VERSION ""

NS_ :

BS_:

BU_: ESX_3CS ION_BMS SEG_BRM_Drive

BO_ 3221225472 VECTOR__INDEPENDENT_SIG_MSG: 0 Vector__XXX
 SG_ Edrv_iAct_LSB : 0|8@1+ (1,0) [0|255] "" Vector__XXX
 SG_ Edrv_iAct_MSB : 0|2@1+ (1,0) [0|3] "A" Vector__XXX
 SG_ Edrv_nAct_LSB : 0|4@1+ (1,0) [0|15] "" Vector__XXX
 SG_ Edrv_nAct_MSB : 0|1@1+ (1,0) [0|1] "rpm" Vector__XXX
 SG_ Edrv_nAct_SB : 0|8@1+ (1,0) [0|255] "" Vector__XXX
 SG_ Edrv_nrAlvCntrAct : 0|4@1+ (1,0) [0|15] "" Vector__XXX
 SG_ Edrv_nrChksAct : 0|8@1+ (1,0) [0|255] "" Vector__XXX
 SG_ Edrv_stOperModAct : 0|4@1+ (1,0) [0|15] "" Vector__XXX
 SG_ Edrv_stRunAct : 0|3@1+ (1,0) [0|7] "" Vector__XXX
 SG_ Edrv_tqAct_LSB : 0|7@1+ (1,0) [0|127] "" Vector__XXX
 SG_ Edrv_tqAct_MSB : 0|4@1+ (1,0) [0|15] "Nm" Vector__XXX
 SG_ Edrv_uAct_LSB : 0|6@1+ (1,0) [0|63] "" Vector__XXX
 SG_ Edrv_uAct_MSB : 0|4@1+ (1,0) [0|15] "V" Vector__XXX
 SG_ Edrv_nrAlvCntrDern : 0|4@1+ (1,0) [0|15] "" Vector__XXX
 SG_ Edrv_nrChksDern : 0|8@1+ (1,0) [0|255] "" Vector__XXX
 SG_ Edrv_ratTCritIvtr : 0|7@1+ (1,0) [0|127] "%" Vector__XXX
 SG_ Edrv_ratTCritMac_LSB : 0|6@1+ (1,0) [0|63] "%" Vector__XXX
 SG_ Edrv_ratTCritMac_MSB : 0|1@1+ (1,0) [0|1] "%" Vector__XXX
 SG_ Edrv_stActDern : 0|4@1+ (1,0) [0|15] "" Vector__XXX
 SG_ Edrv_stFltId_LSB : 0|7@1+ (1,0) [0|127] "" Vector__XXX
 SG_ Edrv_stFltId_MSB : 0|2@1+ (1,0) [0|3] "" Vector__XXX
 SG_ Edrv_tqMaxAvl_LSB : 0|4@1+ (1,0) [0|15] "" Vector__XXX
 SG_ Edrv_tqMaxAvl_MSB : 0|6@1+ (1,0) [0|63] "" Vector__XXX
 SG_ Edrv_tqMinAvl_LSB : 0|2@1+ (1,0) [0|3] "" Vector__XXX
 SG_ Edrv_tqMinAvl_MSB : 0|8@1+ (1,0) [0|255] "" Vector__XXX
 SG_ Eem_iMaxEdrv : 0|8@1+ (2,0) [0|510] "A" Vector__XXX
 SG_ Eem_iMinEdrv : 0|8@1+ (2,-510) [-510|0] "A" Vector__XXX
 SG_ Eem_nrAlvCntrLim : 0|4@1+ (1,0) [0|15] "" Vector__XXX
 SG_ Eem_nrChksLim : 0|8@1+ (1,0) [0|255] "" Vector__XXX
 SG_ Eem_rMvbEdrv : 0|8@1+ (0.005,0.005) [0.005|1.28] "Ohm" Vector__XXX
 SG_ Eem_uDesEdrv : 0|8@1+ (0.1,30) [30|55.5] "V" Vector__XXX
 SG_ Eem_uMaxEdrv : 0|8@1+ (0.2,10) [10|61] "V" Vector__XXX
 SG_ Eem_uMinEdrv : 0|8@1+ (0.2,10) [10|61] "V" Vector__XXX
 SG_ Byte2 : 0|8@1+ (1,0) [0|255] "" Vector__XXX
 SG_ Byte3 : 0|8@1+ (1,0) [0|255] "" Vector__XXX
 SG_ Byte4 : 0|8@1+ (1,0) [0|255] "" Vector__XXX
 SG_ Byte5 : 0|8@1+ (1,0) [0|255] "" Vector__XXX
 SG_ Byte6 : 0|8@1+ (1,0) [0|255] "" Vector__XXX
 SG_ Pt_nrAlvCntrDes : 0|4@1+ (1,0) [0|15] "" Vector__XXX
 SG_ Pt_nrChksDes : 0|8@1+ (1,0) [0|255] "" Vector__XXX
 SG_ Pt_stOperModDesEdrv : 0|4@1+ (1,0) [0|15] "" Vector__XXX
 SG_ Byte_4 : 0|8@1+ (1,0) [0|255] "" Vector__XXX
 SG_ Byte_5 : 0|8@1+ (1,0) [0|255] "" Vector__XXX
 SG_ Byte_6 : 0|8@1+ (1,0) [0|255] "" Vector__XXX
 SG_ Pt_dAirPresEdrv : 0|8@1+ (5,300) [300|1575] "hPa" Vector__XXX
 SG_ Pt_nrAlvCntrVeh1 : 0|4@1+ (1,0) [0|15] "" Vector__XXX
 SG_ Pt_nrChksVeh1 : 0|8@1+ (1,0) [0|255] "" Vector__XXX
 SG_ Pt_tAmbEdrv : 0|8@1+ (1,-40) [-40|215] "�C" Vector__XXX
 SG_ Byte_2 : 0|8@1+ (1,0) [0|255] "" Vector__XXX
 SG_ Byte_3 : 0|8@1+ (1,0) [0|255] "" Vector__XXX
 SG_ Byte_4 : 0|8@1+ (1,0) [0|255] "" Vector__XXX
 SG_ Byte_5 : 0|8@1+ (1,0) [0|255] "" Vector__XXX
 SG_ Pt_nrAlvCntrVeh2 : 0|4@1+ (1,0) [0|15] "" Vector__XXX
 SG_ Pt_nrChksVeh2 : 0|8@1+ (1,0) [0|255] "" Vector__XXX
 SG_ Data_1 : 0|8@1+ (1,0) [0|255] "" Vector__XXX
 SG_ Data_2 : 0|8@1+ (1,0) [0|255] "" Vector__XXX
 SG_ Data_3 : 0|8@1+ (1,0) [0|255] "" Vector__XXX
 SG_ Data_4 : 0|8@1+ (1,0) [0|255] "" Vector__XXX
 SG_ Data_5 : 0|8@1+ (1,0) [0|255] "" Vector__XXX
 SG_ Data_6 : 0|8@1+ (1,0) [0|255] "" Vector__XXX
 SG_ Data_7 : 0|8@1+ (1,0) [0|255] "" Vector__XXX
 SG_ Data_8 : 0|8@1+ (1,0) [0|255] "" Vector__XXX
 SG_ Battery_Voltage_LSB : 0|8@1+ (1,0) [0|255] "" Vector__XXX
 SG_ Battery_Voltage_MSB2 : 0|8@1+ (1,0) [0|255] "" Vector__XXX
 SG_ Battery_Voltage_MSB3 : 0|8@1+ (1,0) [0|255] "" Vector__XXX
 SG_ Battery_Voltage_MSB4 : 0|8@1+ (1,0) [0|255] "" Vector__XXX
 SG_ Max_Voltage_LSB : 0|8@1+ (1,0) [0|255] "" Vector__XXX
 SG_ Max_Voltage_MSB : 0|8@1+ (1,0) [0|255] "" Vector__XXX
 SG_ Min_Voltage_LSB : 0|8@1+ (1,0) [0|255] "" Vector__XXX
 SG_ Min_Voltage_MSB : 0|8@1+ (1,0) [0|255] "" Vector__XXX
 SG_ Battery_Current_LSB : 0|8@1+ (1,0) [0|255] "" Vector__XXX
 SG_ Battery_Current_MSB2 : 0|8@1+ (1,0) [0|255] "" Vector__XXX
 SG_ Battery_Current_MSB3 : 0|8@1+ (1,0) [0|255] "" Vector__XXX
 SG_ Battery_Current_MSB4 : 0|8@1+ (1,0) [0|255] "" Vector__XXX
 SG_ Temperature_Cell_Max_LSB : 0|8@1+ (1,0) [0|255] "" Vector__XXX
 SG_ Temperature_Cell_Max_MSB : 0|8@1+ (1,0) [0|255] "" Vector__XXX
 SG_ Temperature_Cell_Mean_LSB : 0|8@1+ (1,0) [0|255] "" Vector__XXX
 SG_ Temperature_Cell_Mean_MSB : 0|8@1+ (1,0) [0|255] "" Vector__XXX
 SG_ Temperature_Cell_Min_LSB : 0|8@1+ (1,0) [0|255] "" Vector__XXX
 SG_ Temperature_Cell_Min_MSB : 0|8@1+ (1,0) [0|255] "" Vector__XXX
 SG_ Equivalent_Cycle_LSB : 0|8@1+ (1,0) [0|255] "" Vector__XXX
 SG_ Equivalent_Cycle_MSB2 : 0|8@1+ (1,0) [0|255] "" Vector__XXX
 SG_ Equivalent_Cycle_MSB3 : 0|8@1+ (1,0) [0|255] "" Vector__XXX
 SG_ Equivalent_Cycle_MSB4 : 0|8@1+ (1,0) [0|255] "" Vector__XXX
 SG_ State_of_Charge_LSB : 0|8@1+ (1,0) [0|1] "%" Vector__XXX
 SG_ State_of_Charge_MSB : 0|8@1+ (1,0) [0|1] "%" Vector__XXX
 SG_ State_of_Health_LSB : 0|8@1+ (1,0) [0|1] "%" Vector__XXX
 SG_ State_of_Health_MSB : 0|8@1+ (1,0) [0|1] "%" Vector__XXX
 SG_ BLE_wake_up_request : 0|1@1+ (1,0) [0|1] "" Vector__XXX
 SG_ Configuration_loaded : 0|1@1+ (1,0) [0|1] "" Vector__XXX
 SG_ External_power_supply_state : 0|1@1+ (1,0) [0|1] "" Vector__XXX
 SG_ High_SoC_Indication : 0|1@1+ (1,0) [0|1] "" Vector__XXX
 SG_ Is_fan_driven : 0|1@1+ (1,0) [0|1] "" Vector__XXX
 SG_ Is_heater_driven : 0|1@1+ (1,0) [0|1] "" Vector__XXX
 SG_ Is_running_state : 0|1@1+ (1,0) [0|1] "" Vector__XXX
 SG_ Isolated_input_0_state : 0|1@1+ (1,0) [0|1] "" Vector__XXX
 SG_ Isolated_input_1_state : 0|1@1+ (1,0) [0|1] "" Vector__XXX
 SG_ Low_SoC_Indication_1 : 0|1@1+ (1,0) [0|1] "" Vector__XXX
 SG_ Low_SoC_Indication_2 : 0|1@1+ (1,0) [0|1] "" Vector__XXX
 SG_ Low_SoC_Warning : 0|1@1+ (1,0) [0|1] "" Vector__XXX
 SG_ Needs_balancing : 0|1@1+ (1,0) [0|1] "" Vector__XXX
 SG_ No_error_detected : 0|1@1+ (1,0) [0|1] "" Vector__XXX
 SG_ Power_channel_charge : 0|1@1+ (1,0) [0|1] "" Vector__XXX
 SG_ Power_channel_discharge : 0|1@1+ (1,0) [0|1] "" Vector__XXX
 SG_ Power_channel_emergency : 0|1@1+ (1,0) [0|1] "" Vector__XXX
 SG_ Power_channel_fan : 0|1@1+ (1,0) [0|1] "" Vector__XXX
 SG_ Power_channel_heater_Plus : 0|1@1+ (1,0) [0|1] "" Vector__XXX
 SG_ Power_channel_heater_minus : 0|1@1+ (1,0) [0|1] "" Vector__XXX
 SG_ Power_channel_precharge : 0|1@1+ (1,0) [0|1] "" Vector__XXX
 SG_ Sd_conf_file_opening_error : 0|1@1+ (1,0) [0|1] "" Vector__XXX
 SG_ Sd_conf_file_param_error : 0|1@1+ (1,0) [0|1] "" Vector__XXX
 SG_ Sd_init_flag : 0|1@1+ (1,0) [0|1] "" Vector__XXX
 SG_ Start_request : 0|1@1+ (1,0) [0|1] "" Vector__XXX
 SG_ Unused_1bit : 0|1@1+ (1,0) [0|1] "" Vector__XXX
 SG_ power_3V3_state : 0|1@1+ (1,0) [0|1] "" Vector__XXX

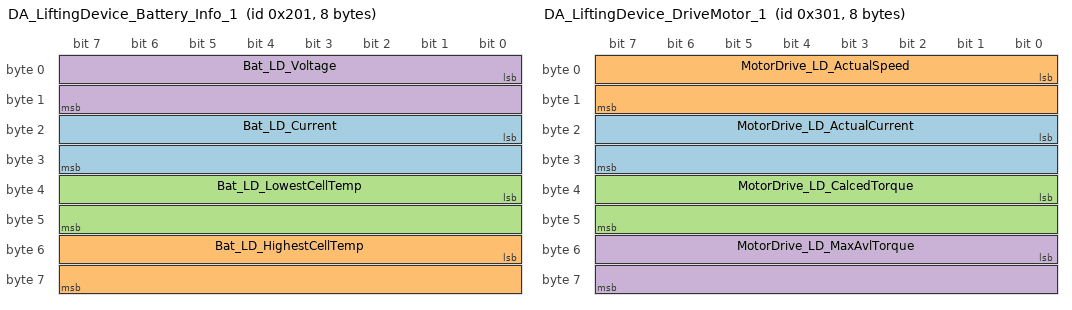
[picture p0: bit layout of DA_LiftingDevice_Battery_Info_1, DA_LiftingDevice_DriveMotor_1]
BO_ 513 DA_LiftingDevice_Battery_Info_1: 8 ESX_3CS
 SG_ Bat_LD_Current : 16|16@1- (0.1,0) [-3276.8|3276.7] "A" Vector__XXX
 SG_ Bat_LD_HighestCellTemp : 48|16@1+ (1,0) [0|65535] "°C" Vector__XXX
 SG_ Bat_LD_LowestCellTemp : 32|16@1+ (1,0) [0|65535] "°C" Vector__XXX
 SG_ Bat_LD_Voltage : 0|16@1+ (0.1,0) [0|6553.5] "V" Vector__XXX

BO_ 769 DA_LiftingDevice_DriveMotor_1: 8 ESX_3CS
 SG_ MotorDrive_LD_ActualCurrent : 16|16@1+ (1,0) [0|65535] "ADC" Vector__XXX
 SG_ MotorDrive_LD_ActualSpeed : 0|16@1- (1,0) [-32768|32767] "rpm" Vector__XXX
 SG_ MotorDrive_LD_CalcedTorque : 32|16@1- (0.1,0) [-3276.8|3276.7] "Nm" Vector__XXX
 SG_ MotorDrive_LD_MaxAvlTorque : 48|16@1- (0.1,0) [-3276.8|3276.7] "Nm" Vector__XXX

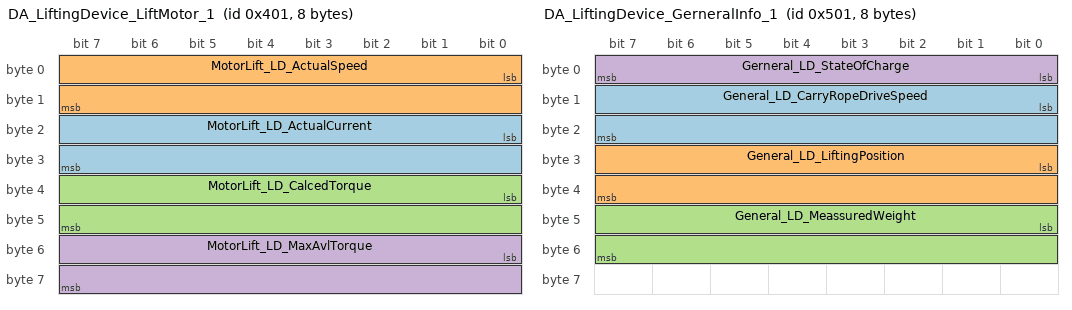
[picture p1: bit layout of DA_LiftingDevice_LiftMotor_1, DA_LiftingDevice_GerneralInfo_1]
BO_ 1025 DA_LiftingDevice_LiftMotor_1: 8 ESX_3CS
 SG_ MotorLift_LD_ActualCurrent : 16|16@1+ (1,0) [0|65535] "ADC" Vector__XXX
 SG_ MotorLift_LD_ActualSpeed : 0|16@1- (1,0) [-32768|32767] "rpm" Vector__XXX
 SG_ MotorLift_LD_CalcedTorque : 32|16@1- (0.1,0) [-3276.8|3276.7] "Nm" Vector__XXX
 SG_ MotorLift_LD_MaxAvlTorque : 48|16@1+ (0.1,0) [0|6553.5] "Nm" Vector__XXX

BO_ 1281 DA_LiftingDevice_GerneralInfo_1: 8 ESX_3CS
 SG_ General_LD_CarryRopeDriveSpeed : 8|16@1- (0.01,0) [-327.68|327.67] "m/s" Vector__XXX
 SG_ General_LD_LiftingPosition : 24|16@1- (1,0) [-32768|32767] "digits" Vector__XXX
 SG_ General_LD_MeassuredWeight : 40|16@1+ (1,0) [0|65535] "kg" Vector__XXX
 SG_ Gerneral_LD_StateOfCharge : 0|8@1+ (1,0) [0|255] "%" Vector__XXX

CM_ BO_ 3221225472 "This is a message for not used signals, created by Vector CANdb++ DBC OLE DB Provider.";
CM_ SG_ 3221225472 State_of_Charge_LSB "29-12-2020 : Reviewed : Datta";
CM_ SG_ 3221225472 State_of_Charge_MSB "29-12-2020 : Reviewed : Datta";
CM_ SG_ 3221225472 State_of_Health_LSB "29-12-2020 : Reviewed : Datta";
CM_ SG_ 3221225472 State_of_Health_MSB "29-12-2020 : Reviewed : Datta";
BA_DEF_  "DBName" STRING ;
BA_DEF_ BO_  "GenMsgCycleTime" INT 0 0;
BA_DEF_ BO_  "GenMsgSendType" ENUM  "Cyclic","OnEvent";
BA_DEF_ SG_  "GenSigStartValue" INT 0 0;
BA_DEF_DEF_  "DBName" "";
BA_DEF_DEF_  "GenMsgCycleTime" 0;
BA_DEF_DEF_  "GenMsgSendType" "";
BA_DEF_DEF_  "GenSigStartValue" 0;
BA_ "DBName" "CAN1";
BA_ "GenMsgSendType" BO_ 513 0;
BA_ "GenMsgCycleTime" BO_ 513 10;
BA_ "GenMsgSendType" BO_ 769 0;
BA_ "GenMsgCycleTime" BO_ 769 100;
BA_ "GenMsgSendType" BO_ 1025 0;
BA_ "GenMsgCycleTime" BO_ 1025 100;
BA_ "GenMsgSendType" BO_ 1281 0;
BA_ "GenMsgCycleTime" BO_ 1281 100;
BA_ "GenSigStartValue" SG_ 3221225472 Edrv_iAct_MSB 1;
BA_ "GenSigStartValue" SG_ 3221225472 Edrv_nAct_MSB 1;
BA_ "GenSigStartValue" SG_ 3221225472 Edrv_tqAct_MSB 1;
BA_ "GenSigStartValue" SG_ 3221225472 Eem_iMinEdrv 255;
BA_ "GenSigStartValue" SG_ 3221225472 Pt_tAmbEdrv 40;
